AUTOSAR XML (schema 00051)
standard types defined: boolean, uint16, uint32, uint8, Boolean, UInt16, UInt32, UInt8
package /FV/Comm
  pdu DecelIPdu: length=8  # Authentic/plain I-PDU DecelIPdu
    signal DecelISig: start 0, 64 bit, little-endian, system signal DecelSSig
  pdu EngineIPdu: length=8  # Authentic/plain I-PDU EngineIPdu
    signal EngineISig: start 0, 64 bit, little-endian, system signal EngineSSig
  pdu NavIPdu: length=8  # Authentic/plain I-PDU NavIPdu
    signal NavISig: start 0, 64 bit, little-endian, system signal NavSSig
  pdu TcuGwIPdu: length=8  # Authentic/plain I-PDU TcuGwIPdu
    signal TcuGwISig: start 0, 64 bit, little-endian, system signal TcuGwSSig
  pdu V2xIPdu: length=8  # Authentic/plain I-PDU V2xIPdu
    signal V2xISig: start 0, 64 bit, little-endian, system signal V2xSSig
package /FV/If
  23 x sender receiver interface:
    AmbientCmd  # Sender/receiver interface AmbientCmd
      data color: type=Byte8Array
    BodyCmd  # Sender/receiver interface BodyCmd
      data cmd: type=Byte8Array
    BrakeForce  # Sender/receiver interface BrakeForce
      data force: type=Byte8Array
    ComfortMode  # Sender/receiver interface ComfortMode
      data mode: type=Byte8Array
    DecelReq  # Sender/receiver interface DecelReq
      data decel: type=Byte8Array
    DiagCmd  # Sender/receiver interface DiagCmd
      data cmd: type=Byte8Array
    DoorCmd  # Sender/receiver interface DoorCmd
      data lock: type=Byte8Array
    EmisData  # Sender/receiver interface EmisData
      data emis: type=Byte8Array
    EngineCmd  # Sender/receiver interface EngineCmd
      data torque: type=Byte8Array
    FwPolicy  # Sender/receiver interface FwPolicy
      data rule: type=Byte8Array
    HvacCmd  # Sender/receiver interface HvacCmd
      data temp: type=Byte8Array
    LaneData  # Sender/receiver interface LaneData
      data lanes: type=Byte8Array
    LightCmd  # Sender/receiver interface LightCmd
      data level: type=Byte8Array
    MediaReq  # Sender/receiver interface MediaReq
      data payload: type=Byte8Array
    MediaStream  # Sender/receiver interface MediaStream
      data stream: type=Byte8Array
    NavRoute  # Sender/receiver interface NavRoute
      data route: type=Byte8Array
    ObjData  # Sender/receiver interface ObjData
      data objects: type=Byte8Array
    OtaCmd  # Sender/receiver interface OtaCmd
      data pkg: type=Byte8Array
    RemoteSvc  # Sender/receiver interface RemoteSvc
      data val: type=Byte8Array
    SteerAngle  # Sender/receiver interface SteerAngle
      data angle: type=Byte8Array
    TailCmd  # Sender/receiver interface TailCmd
      data level: type=Byte8Array
    TransGear  # Sender/receiver interface TransGear
      data gear: type=Byte8Array
    V2xMsg  # Sender/receiver interface V2xMsg
      data msg: type=Byte8Array
package /FV/Network
  can cluster Backbone: baudrate=500000, can-fd-baudrate=2000000
    can physical channel Ch0
      comm-connectors:
        AdasEcu/CanConn0
        BodyEcu/CanConn0
        ChassisEcu/CanConn0
        GatewayEcu/CanConn0
        IviEcu/CanConn0
        LightEcu/CanConn0
        PtEcu/CanConn0
        TelematicsEcu/CanConn0
      frame Frame_BodyIPdu: id 0x100, from GatewayEcu, to BodyEcu, frame-length=8, can-addressing-mode=STANDARD, can-frame-rx-behavior=CAN-FD, can-frame-tx-behavior=CAN-FD
        pdu BodyIPdu: length=8  # Authentic/plain I-PDU BodyIPdu
          signal BodyISig: start 0, 64 bit, little-endian, system signal BodySSig
      frame Frame_ComfortIPdu: id 0x101, from GatewayEcu, frame-length=8, can-addressing-mode=STANDARD, can-frame-rx-behavior=CAN-FD, can-frame-tx-behavior=CAN-FD
        pdu ComfortIPdu: length=8  # Authentic/plain I-PDU ComfortIPdu
          signal ComfortISig: start 0, 64 bit, little-endian, system signal ComfortSSig
      frame Frame_DecelSecuredIPdu: id 0x102, frame-length=16, can-addressing-mode=STANDARD, can-frame-rx-behavior=CAN-FD, can-frame-tx-behavior=CAN-FD
        secured i pdu DecelSecuredIPdu: length=13, payload=Trg_DecelIPdu, secure-communication-props={auth-algorithm=CMAC, auth-info-tx-length=32, data-id=259, freshness-value-id=4, freshness-value-length=8, freshness-value-tx-length=8}, use-as-cryptographic-i-pdu=false  # SecOC secured I-PDU DecelSecuredIPdu
      frame Frame_EngineSecuredIPdu: id 0x103, frame-length=16, can-addressing-mode=STANDARD, can-frame-rx-behavior=CAN-FD, can-frame-tx-behavior=CAN-FD
        secured i pdu EngineSecuredIPdu: length=13, payload=Trg_EngineIPdu, secure-communication-props={auth-algorithm=CMAC, auth-info-tx-length=32, data-id=260, freshness-value-id=5, freshness-value-length=8, freshness-value-tx-length=8}, use-as-cryptographic-i-pdu=false  # SecOC secured I-PDU EngineSecuredIPdu
      frame Frame_LightIPdu: id 0x104, from GatewayEcu, to LightEcu, frame-length=8, can-addressing-mode=STANDARD, can-frame-rx-behavior=CAN-FD, can-frame-tx-behavior=CAN-FD
        pdu LightIPdu: length=8  # Authentic/plain I-PDU LightIPdu
          signal LightISig: start 0, 64 bit, little-endian, system signal LightSSig
      frame Frame_NavSecuredIPdu: id 0x105, frame-length=16, can-addressing-mode=STANDARD, can-frame-rx-behavior=CAN-FD, can-frame-tx-behavior=CAN-FD
        secured i pdu NavSecuredIPdu: length=13, payload=Trg_NavIPdu, secure-communication-props={auth-algorithm=CMAC, auth-info-tx-length=32, data-id=256, freshness-value-id=1, freshness-value-length=8, freshness-value-tx-length=8}, use-as-cryptographic-i-pdu=false  # SecOC secured I-PDU NavSecuredIPdu
      frame Frame_OtaIPdu: id 0x106, from TelematicsEcu, to GatewayEcu, frame-length=8, can-addressing-mode=STANDARD, can-frame-rx-behavior=CAN-FD, can-frame-tx-behavior=CAN-FD
        pdu OtaIPdu: length=8  # Authentic/plain I-PDU OtaIPdu
          signal OtaISig: start 0, 64 bit, little-endian, system signal OtaSSig
      frame Frame_TcuGwSecuredIPdu: id 0x107, frame-length=16, can-addressing-mode=STANDARD, can-frame-rx-behavior=CAN-FD, can-frame-tx-behavior=CAN-FD
        secured i pdu TcuGwSecuredIPdu: length=13, payload=Trg_TcuGwIPdu, secure-communication-props={auth-algorithm=CMAC, auth-info-tx-length=32, data-id=257, freshness-value-id=2, freshness-value-length=8, freshness-value-tx-length=8}, use-as-cryptographic-i-pdu=false  # SecOC secured I-PDU TcuGwSecuredIPdu
      frame Frame_V2xSecuredIPdu: id 0x108, frame-length=16, can-addressing-mode=STANDARD, can-frame-rx-behavior=CAN-FD, can-frame-tx-behavior=CAN-FD
        secured i pdu V2xSecuredIPdu: length=13, payload=Trg_V2xIPdu, secure-communication-props={auth-algorithm=CMAC, auth-info-tx-length=32, data-id=258, freshness-value-id=3, freshness-value-length=8, freshness-value-tx-length=8}, use-as-cryptographic-i-pdu=false  # SecOC secured I-PDU V2xSecuredIPdu
      pdu triggering Trg_DecelIPdu: pdu=DecelIPdu, from AdasEcu, to ChassisEcu
      pdu triggering Trg_EngineIPdu: pdu=EngineIPdu, from GatewayEcu, to PtEcu
      pdu triggering Trg_NavIPdu: pdu=NavIPdu, from IviEcu, to GatewayEcu
      pdu triggering Trg_TcuGwIPdu: pdu=TcuGwIPdu, from TelematicsEcu, to GatewayEcu
      pdu triggering Trg_V2xIPdu: pdu=V2xIPdu, from TelematicsEcu, to GatewayEcu
package /FV/Swc
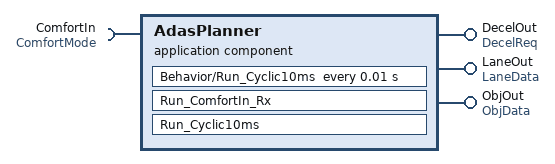
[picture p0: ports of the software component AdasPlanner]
  application sw component type AdasPlanner  # Application software component type AdasPlanner
    require port ComfortIn: required-interface=ComfortMode
    provide port DecelOut: provided-interface=DecelReq
    provide port LaneOut: provided-interface=LaneData
    provide port ObjOut: provided-interface=ObjData
    behavior Behavior
      data received event Dre_ComfortIn: start-on-event=Run_ComfortIn_Rx, data=ComfortIn.mode
      timing event Tev_Cyclic10ms: start-on-event=Behavior/Run_Cyclic10ms, period=0.01
      runnable Run_ComfortIn_Rx
        data-receive-point-by-arguments:
          access Rcv_ComfortIn: accessed-variable=ComfortIn.mode
      runnable Run_Cyclic10ms
        data-send-points:
          access Snd_DecelOut: accessed-variable=DecelOut.decel
          access Snd_LaneOut: accessed-variable=LaneOut.lanes
          access Snd_ObjOut: accessed-variable=ObjOut.objects
  swc implementation AdasPlanner_Impl: programming-language=C, sw-version=1.0.0, behavior=AdasPlanner/Behavior
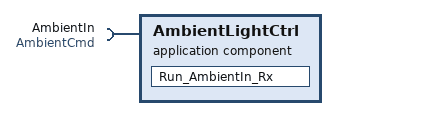
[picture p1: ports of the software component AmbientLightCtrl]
  application sw component type AmbientLightCtrl  # Application software component type AmbientLightCtrl
    require port AmbientIn: required-interface=AmbientCmd
    behavior Behavior
      data received event Dre_AmbientIn: start-on-event=Run_AmbientIn_Rx, data=AmbientIn.color
      runnable Run_AmbientIn_Rx
        data-receive-point-by-arguments:
          access Rcv_AmbientIn: accessed-variable=AmbientIn.color
  swc implementation AmbientLightCtrl_Impl: programming-language=C, sw-version=1.0.0, behavior=AmbientLightCtrl/Behavior
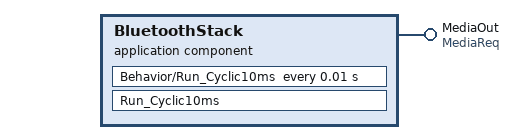
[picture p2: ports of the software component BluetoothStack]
  application sw component type BluetoothStack  # Application software component type BluetoothStack
    provide port MediaOut: provided-interface=MediaReq
    behavior Behavior
      timing event Tev_Cyclic10ms: start-on-event=Behavior/Run_Cyclic10ms, period=0.01
      runnable Run_Cyclic10ms
        data-send-points:
          access Snd_MediaOut: accessed-variable=MediaOut.payload
  swc implementation BluetoothStack_Impl: programming-language=C, sw-version=1.0.0, behavior=BluetoothStack/Behavior
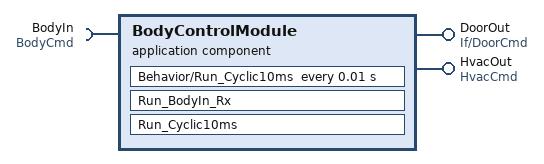
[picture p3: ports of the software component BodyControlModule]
  application sw component type BodyControlModule  # Application software component type BodyControlModule
    require port BodyIn: required-interface=BodyCmd
    provide port DoorOut: provided-interface=If/DoorCmd
    provide port HvacOut: provided-interface=HvacCmd
    behavior Behavior
      data received event Dre_BodyIn: start-on-event=Run_BodyIn_Rx, data=BodyIn.cmd
      timing event Tev_Cyclic10ms: start-on-event=Behavior/Run_Cyclic10ms, period=0.01
      runnable Run_BodyIn_Rx
        data-receive-point-by-arguments:
          access Rcv_BodyIn: accessed-variable=BodyIn.cmd
      runnable Run_Cyclic10ms
        data-send-points:
          access Snd_DoorOut: accessed-variable=DoorOut.lock
          access Snd_HvacOut: accessed-variable=HvacOut.temp
  swc implementation BodyControlModule_Impl: programming-language=C, sw-version=1.0.0, behavior=BodyControlModule/Behavior
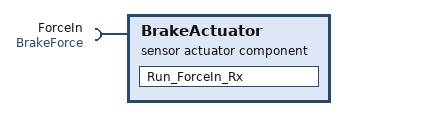
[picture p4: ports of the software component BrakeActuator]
  sensor actuator sw component type BrakeActuator  # Sensor/actuator software component type BrakeActuator
    require port ForceIn: required-interface=BrakeForce
    behavior Behavior
      data received event Dre_ForceIn: start-on-event=Run_ForceIn_Rx, data=ForceIn.force
      runnable Run_ForceIn_Rx
        data-receive-point-by-arguments:
          access Rcv_ForceIn: accessed-variable=ForceIn.force
  swc implementation BrakeActuator_Impl: programming-language=C, sw-version=1.0.0, behavior=BrakeActuator/Behavior
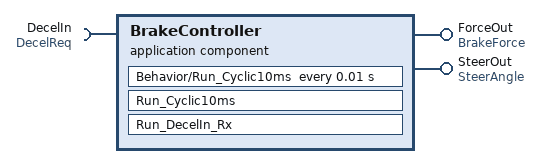
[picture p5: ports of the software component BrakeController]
  application sw component type BrakeController  # Application software component type BrakeController
    require port DecelIn: required-interface=DecelReq
    provide port ForceOut: provided-interface=BrakeForce
    provide port SteerOut: provided-interface=SteerAngle
    behavior Behavior
      data received event Dre_DecelIn: start-on-event=Run_DecelIn_Rx, data=DecelIn.decel
      timing event Tev_Cyclic10ms: start-on-event=Behavior/Run_Cyclic10ms, period=0.01
      runnable Run_Cyclic10ms
        data-send-points:
          access Snd_ForceOut: accessed-variable=ForceOut.force
          access Snd_SteerOut: accessed-variable=SteerOut.angle
      runnable Run_DecelIn_Rx
        data-receive-point-by-arguments:
          access Rcv_DecelIn: accessed-variable=DecelIn.decel
  swc implementation BrakeController_Impl: programming-language=C, sw-version=1.0.0, behavior=BrakeController/Behavior
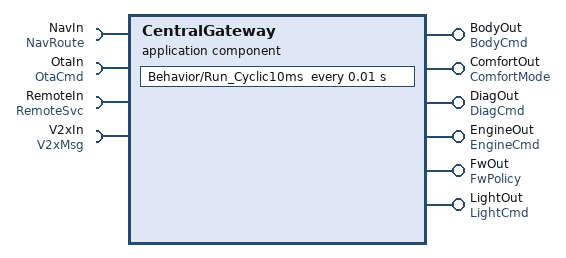
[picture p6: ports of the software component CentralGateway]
  application sw component type CentralGateway  # Application software component type CentralGateway
    6 x provide port:
      BodyOut: provided-interface=BodyCmd
      ComfortOut: provided-interface=ComfortMode
      DiagOut: provided-interface=DiagCmd
      EngineOut: provided-interface=EngineCmd
      FwOut: provided-interface=FwPolicy
      LightOut: provided-interface=LightCmd
    4 x require port:
      NavIn: required-interface=NavRoute
      OtaIn: required-interface=OtaCmd
      RemoteIn: required-interface=RemoteSvc
      V2xIn: required-interface=V2xMsg
    behavior Behavior
      4 x data received event:
        Dre_NavIn: start-on-event=Run_NavIn_Rx, data=NavIn.route
        Dre_OtaIn: start-on-event=Run_OtaIn_Rx, data=OtaIn.pkg
        Dre_RemoteIn: start-on-event=Run_RemoteIn_Rx, data=RemoteIn.val
        Dre_V2xIn: start-on-event=Run_V2xIn_Rx, data=V2xIn.msg
      timing event Tev_Cyclic10ms: start-on-event=Behavior/Run_Cyclic10ms, period=0.01
      5 x runnable:
        Run_Cyclic10ms
          data-send-points:
            6 x access:
              Snd_BodyOut: accessed-variable=BodyOut.cmd
              Snd_ComfortOut: accessed-variable=ComfortOut.mode
              Snd_DiagOut: accessed-variable=DiagOut.cmd
              Snd_EngineOut: accessed-variable=EngineOut.torque
              Snd_FwOut: accessed-variable=FwOut.rule
              Snd_LightOut: accessed-variable=LightOut.level
        Run_NavIn_Rx
          data-receive-point-by-arguments:
            access Rcv_NavIn: accessed-variable=NavIn.route
        Run_OtaIn_Rx
          data-receive-point-by-arguments:
            access Rcv_OtaIn: accessed-variable=OtaIn.pkg
        Run_RemoteIn_Rx
          data-receive-point-by-arguments:
            access Rcv_RemoteIn: accessed-variable=RemoteIn.val
        Run_V2xIn_Rx
          data-receive-point-by-arguments:
            access Rcv_V2xIn: accessed-variable=V2xIn.msg
  swc implementation CentralGateway_Impl: programming-language=C, sw-version=1.0.0, behavior=CentralGateway/Behavior
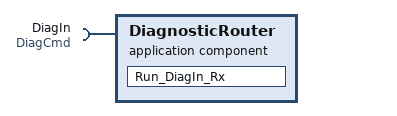
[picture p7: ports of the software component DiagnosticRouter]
  application sw component type DiagnosticRouter  # Application software component type DiagnosticRouter
    require port DiagIn: required-interface=DiagCmd
    behavior Behavior
      data received event Dre_DiagIn: start-on-event=Run_DiagIn_Rx, data=DiagIn.cmd
      runnable Run_DiagIn_Rx
        data-receive-point-by-arguments:
          access Rcv_DiagIn: accessed-variable=DiagIn.cmd
  swc implementation DiagnosticRouter_Impl: programming-language=C, sw-version=1.0.0, behavior=DiagnosticRouter/Behavior
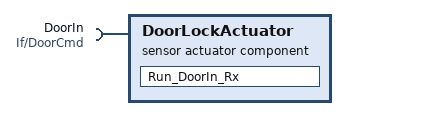
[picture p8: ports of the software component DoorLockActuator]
  sensor actuator sw component type DoorLockActuator  # Sensor/actuator software component type DoorLockActuator
    require port DoorIn: required-interface=If/DoorCmd
    behavior Behavior
      data received event Dre_DoorIn: start-on-event=Run_DoorIn_Rx, data=DoorIn.lock
      runnable Run_DoorIn_Rx
        data-receive-point-by-arguments:
          access Rcv_DoorIn: accessed-variable=DoorIn.lock
  swc implementation DoorLockActuator_Impl: programming-language=C, sw-version=1.0.0, behavior=DoorLockActuator/Behavior
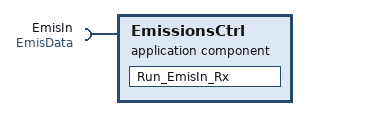
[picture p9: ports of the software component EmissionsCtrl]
  application sw component type EmissionsCtrl  # Application software component type EmissionsCtrl
    require port EmisIn: required-interface=EmisData
    behavior Behavior
      data received event Dre_EmisIn: start-on-event=Run_EmisIn_Rx, data=EmisIn.emis
      runnable Run_EmisIn_Rx
        data-receive-point-by-arguments:
          access Rcv_EmisIn: accessed-variable=EmisIn.emis
  swc implementation EmissionsCtrl_Impl: programming-language=C, sw-version=1.0.0, behavior=EmissionsCtrl/Behavior
  application sw component type EngineController  # Application software component type EngineController
    provide port EmisOut: provided-interface=EmisData
    require port EngIn: required-interface=EngineCmd
    provide port TransOut: provided-interface=TransGear
    behavior Behavior
      data received event Dre_EngIn: start-on-event=Run_EngIn_Rx, data=EngIn.torque
      timing event Tev_Cyclic10ms: start-on-event=Behavior/Run_Cyclic10ms, period=0.01
      runnable Run_Cyclic10ms
        data-send-points:
          access Snd_EmisOut: accessed-variable=EmisOut.emis
          access Snd_TransOut: accessed-variable=TransOut.gear
      runnable Run_EngIn_Rx
        data-receive-point-by-arguments:
          access Rcv_EngIn: accessed-variable=EngIn.torque
  swc implementation EngineController_Impl: programming-language=C, sw-version=1.0.0, behavior=EngineController/Behavior
  application sw component type FirewallManager  # Application software component type FirewallManager
    require port FwIn: required-interface=FwPolicy
    behavior Behavior
      data received event Dre_FwIn: start-on-event=Run_FwIn_Rx, data=FwIn.rule
      runnable Run_FwIn_Rx
        data-receive-point-by-arguments:
          access Rcv_FwIn: accessed-variable=FwIn.rule
  swc implementation FirewallManager_Impl: programming-language=C, sw-version=1.0.0, behavior=FirewallManager/Behavior
  composition sw component type FullVehicle  # Composition FullVehicle
    24 x component:
      adas: type=AdasPlanner
      ambientLight: type=AmbientLightCtrl
      bcm: type=BodyControlModule
      brakeAct: type=BrakeActuator
      brakeCtl: type=BrakeController
      btStack: type=BluetoothStack
      cgw: type=CentralGateway
      diagRouter: type=DiagnosticRouter
      doorLock: type=DoorLockActuator
      emisCtl: type=EmissionsCtrl
      engineCtl: type=EngineController
      firewallMgr: type=FirewallManager
      headlight: type=HeadlightCtrl
      hvacCtl: type=HvacController
      ivi: type=InfotainmentHU
      laneKeep: type=LaneKeepAssist
      mediaPlayer: type=MediaPlayer
      objDetect: type=ObjectDetector
      otaManager: type=OtaManager
      steerCtl: type=SteeringController
      taillight: type=TaillightCtrl
      tcu: type=Swc/TelematicsUnit
      transCtl: type=TransmissionCtrl
      v2xStack: type=V2xStack
    connect adas.DecelOut -> brakeCtl.DecelIn
    connect adas.LaneOut -> laneKeep.LaneIn
    connect adas.ObjOut -> objDetect.ObjIn
    connect bcm.DoorOut -> doorLock.DoorIn
    connect bcm.HvacOut -> hvacCtl.HvacIn
    connect brakeCtl.ForceOut -> brakeAct.ForceIn
    connect brakeCtl.SteerOut -> steerCtl.SteerIn
    connect btStack.MediaOut -> ivi.MediaIn
    connect engineCtl.EmisOut -> emisCtl.EmisIn
    connect engineCtl.TransOut -> transCtl.TransIn
    connect cgw.BodyOut -> bcm.BodyIn
    connect cgw.DiagOut -> diagRouter.DiagIn
    connect cgw.EngineOut -> engineCtl.EngIn
    connect cgw.FwOut -> firewallMgr.FwIn
    connect cgw.LightOut -> headlight.LightIn
    connect headlight.AmbientOut -> ambientLight.AmbientIn
    connect headlight.TailOut -> taillight.TailIn
    connect ivi.NavOut -> cgw.NavIn
    connect ivi.StreamOut -> mediaPlayer.StreamIn
    connect otaManager.OtaOut -> cgw.OtaIn
    connect tcu.RemoteOut -> cgw.RemoteIn
    connect v2xStack.V2xOut -> cgw.V2xIn
  application sw component type HeadlightCtrl  # Application software component type HeadlightCtrl
    provide port AmbientOut: provided-interface=AmbientCmd
    require port LightIn: required-interface=LightCmd
    provide port TailOut: provided-interface=TailCmd
    behavior Behavior
      data received event Dre_LightIn: start-on-event=Run_LightIn_Rx, data=LightIn.level
      timing event Tev_Cyclic10ms: start-on-event=Behavior/Run_Cyclic10ms, period=0.01
      runnable Run_Cyclic10ms
        data-send-points:
          access Snd_AmbientOut: accessed-variable=AmbientOut.color
          access Snd_TailOut: accessed-variable=TailOut.level
      runnable Run_LightIn_Rx
        data-receive-point-by-arguments:
          access Rcv_LightIn: accessed-variable=LightIn.level
  swc implementation HeadlightCtrl_Impl: programming-language=C, sw-version=1.0.0, behavior=HeadlightCtrl/Behavior
  application sw component type HvacController  # Application software component type HvacController
    require port HvacIn: required-interface=HvacCmd
    behavior Behavior
      data received event Dre_HvacIn: start-on-event=Run_HvacIn_Rx, data=HvacIn.temp
      runnable Run_HvacIn_Rx
        data-receive-point-by-arguments:
          access Rcv_HvacIn: accessed-variable=HvacIn.temp
  swc implementation HvacController_Impl: programming-language=C, sw-version=1.0.0, behavior=HvacController/Behavior
  application sw component type InfotainmentHU  # Application software component type InfotainmentHU
    require port MediaIn: required-interface=MediaReq
    provide port NavOut: provided-interface=NavRoute
    provide port StreamOut: provided-interface=MediaStream
    behavior Behavior
      data received event Dre_MediaIn: start-on-event=Run_MediaIn_Rx, data=MediaIn.payload
      timing event Tev_Cyclic10ms: start-on-event=Behavior/Run_Cyclic10ms, period=0.01
      runnable Run_Cyclic10ms
        data-send-points:
          access Snd_NavOut: accessed-variable=NavOut.route
          access Snd_StreamOut: accessed-variable=StreamOut.stream
      runnable Run_MediaIn_Rx
        data-receive-point-by-arguments:
          access Rcv_MediaIn: accessed-variable=MediaIn.payload
  swc implementation InfotainmentHU_Impl: programming-language=C, sw-version=1.0.0, behavior=InfotainmentHU/Behavior
  application sw component type LaneKeepAssist  # Application software component type LaneKeepAssist
    require port LaneIn: required-interface=LaneData
    behavior Behavior
      data received event Dre_LaneIn: start-on-event=Run_LaneIn_Rx, data=LaneIn.lanes
      runnable Run_LaneIn_Rx
        data-receive-point-by-arguments:
          access Rcv_LaneIn: accessed-variable=LaneIn.lanes
  swc implementation LaneKeepAssist_Impl: programming-language=C, sw-version=1.0.0, behavior=LaneKeepAssist/Behavior
  application sw component type MediaPlayer  # Application software component type MediaPlayer
    require port StreamIn: required-interface=MediaStream
    behavior Behavior
      data received event Dre_StreamIn: start-on-event=Run_StreamIn_Rx, data=StreamIn.stream
      runnable Run_StreamIn_Rx
        data-receive-point-by-arguments:
          access Rcv_StreamIn: accessed-variable=StreamIn.stream
  swc implementation MediaPlayer_Impl: programming-language=C, sw-version=1.0.0, behavior=MediaPlayer/Behavior
  application sw component type ObjectDetector  # Application software component type ObjectDetector
    require port ObjIn: required-interface=ObjData
    behavior Behavior
      data received event Dre_ObjIn: start-on-event=Run_ObjIn_Rx, data=ObjIn.objects
      runnable Run_ObjIn_Rx
        data-receive-point-by-arguments:
          access Rcv_ObjIn: accessed-variable=ObjIn.objects
  swc implementation ObjectDetector_Impl: programming-language=C, sw-version=1.0.0, behavior=ObjectDetector/Behavior
  application sw component type OtaManager  # Application software component type OtaManager
    provide port OtaOut: provided-interface=OtaCmd
    behavior Behavior
      timing event Tev_Cyclic10ms: start-on-event=Behavior/Run_Cyclic10ms, period=0.01
      runnable Run_Cyclic10ms
        data-send-points:
          access Snd_OtaOut: accessed-variable=OtaOut.pkg
  swc implementation OtaManager_Impl: programming-language=C, sw-version=1.0.0, behavior=OtaManager/Behavior
  sensor actuator sw component type SteeringController  # Sensor/actuator software component type SteeringController
    require port SteerIn: required-interface=SteerAngle
    behavior Behavior
      data received event Dre_SteerIn: start-on-event=Run_SteerIn_Rx, data=SteerIn.angle
      runnable Run_SteerIn_Rx
        data-receive-point-by-arguments:
          access Rcv_SteerIn: accessed-variable=SteerIn.angle
  swc implementation SteeringController_Impl: programming-language=C, sw-version=1.0.0, behavior=SteeringController/Behavior
  sensor actuator sw component type TaillightCtrl  # Sensor/actuator software component type TaillightCtrl
    require port TailIn: required-interface=TailCmd
    behavior Behavior
      data received event Dre_TailIn: start-on-event=Run_TailIn_Rx, data=TailIn.level
      runnable Run_TailIn_Rx
        data-receive-point-by-arguments:
          access Rcv_TailIn: accessed-variable=TailIn.level
  swc implementation TaillightCtrl_Impl: programming-language=C, sw-version=1.0.0, behavior=TaillightCtrl/Behavior
  application sw component type TelematicsUnit  # Application software component type TelematicsUnit
    provide port RemoteOut: provided-interface=RemoteSvc
    behavior Behavior
      timing event Tev_Cyclic10ms: start-on-event=Behavior/Run_Cyclic10ms, period=0.01
      runnable Run_Cyclic10ms
        data-send-points:
          access Snd_RemoteOut: accessed-variable=RemoteOut.val
  swc implementation TelematicsUnit_Impl: programming-language=C, sw-version=1.0.0, behavior=TelematicsUnit/Behavior
  application sw component type TransmissionCtrl  # Application software component type TransmissionCtrl
    require port TransIn: required-interface=TransGear
    behavior Behavior
      data received event Dre_TransIn: start-on-event=Run_TransIn_Rx, data=TransIn.gear
      runnable Run_TransIn_Rx
        data-receive-point-by-arguments:
          access Rcv_TransIn: accessed-variable=TransIn.gear
  swc implementation TransmissionCtrl_Impl: programming-language=C, sw-version=1.0.0, behavior=TransmissionCtrl/Behavior
  application sw component type V2xStack  # Application software component type V2xStack
    provide port V2xOut: provided-interface=V2xMsg
    behavior Behavior
      timing event Tev_Cyclic10ms: start-on-event=Behavior/Run_Cyclic10ms, period=0.01
      runnable Run_Cyclic10ms
        data-send-points:
          access Snd_V2xOut: accessed-variable=V2xOut.msg
  swc implementation V2xStack_Impl: programming-language=C, sw-version=1.0.0, behavior=V2xStack/Behavior
package /FV/Topology
  ecu instance AdasEcu: sleep-mode-supported=false, wake-up-over-bus-supported=false  # ECU instance AdasEcu
    can communication controller CanCtrl0: wake-up-by-controller-supported=false
    can communication connector CanConn0: comm-controller=AdasEcu/CanCtrl0
  ecu instance BodyEcu: sleep-mode-supported=false, wake-up-over-bus-supported=false  # ECU instance BodyEcu
    can communication controller CanCtrl0: wake-up-by-controller-supported=false
    can communication connector CanConn0: comm-controller=BodyEcu/CanCtrl0
  ecu instance ChassisEcu: sleep-mode-supported=false, wake-up-over-bus-supported=false  # ECU instance ChassisEcu
    can communication controller CanCtrl0: wake-up-by-controller-supported=false
    can communication connector CanConn0: comm-controller=ChassisEcu/CanCtrl0
  system FullVeh: category=SYSTEM_EXTRACT  # System extract FullVeh
    system mapping Map
      data-mappings:
        data-element=Root.DecelOut.decel, system-signal=DecelSSig
        data-element=Root.BodyOut.cmd, system-signal=BodySSig
        data-element=Root.ComfortOut.mode, system-signal=ComfortSSig
        data-element=Root.EngineOut.torque, system-signal=EngineSSig
        data-element=Root.LightOut.level, system-signal=LightSSig
        data-element=Root.NavOut.route, system-signal=NavSSig
        data-element=Root.OtaOut.pkg, system-signal=OtaSSig
        data-element=Root.RemoteOut.val, system-signal=TcuGwSSig
        data-element=Root.V2xOut.msg, system-signal=V2xSSig
      sw-mappings:
        8 x swc to ecu mapping:
          ToAdas: component=[adas, laneKeep, objDetect], ecu-instance=AdasEcu
          ToBody: component=[bcm, doorLock, hvacCtl], ecu-instance=Topology/BodyEcu
          ToChassis: component=[brakeAct, brakeCtl, steerCtl], ecu-instance=ChassisEcu
          ToGateway: component=[cgw, diagRouter, firewallMgr], ecu-instance=Topology/GatewayEcu
          ToIvi: component=[btStack, ivi, mediaPlayer], ecu-instance=IviEcu
          ToLight: component=[ambientLight, headlight, taillight], ecu-instance=LightEcu
          ToPt: component=[emisCtl, engineCtl, transCtl], ecu-instance=PtEcu
          ToTelematics: component=[otaManager, tcu, v2xStack], ecu-instance=Topology/TelematicsEcu
    root-software-compositions:
      root sw composition prototype Root: software-composition=FullVehicle
  5 x ecu instance, all with sleep-mode-supported=false, wake-up-over-bus-supported=false:
    GatewayEcu  # ECU instance GatewayEcu
      can communication controller CanCtrl0: wake-up-by-controller-supported=false
      can communication connector CanConn0: comm-controller=GatewayEcu/CanCtrl0
    IviEcu  # ECU instance IviEcu
      can communication controller CanCtrl0: wake-up-by-controller-supported=false
      can communication connector CanConn0: comm-controller=IviEcu/CanCtrl0
    LightEcu  # ECU instance LightEcu
      can communication controller CanCtrl0: wake-up-by-controller-supported=false
      can communication connector CanConn0: comm-controller=LightEcu/CanCtrl0
    PtEcu  # ECU instance PtEcu
      can communication controller CanCtrl0: wake-up-by-controller-supported=false
      can communication connector CanConn0: comm-controller=PtEcu/CanCtrl0
    TelematicsEcu  # ECU instance TelematicsEcu
      can communication controller CanCtrl0: wake-up-by-controller-supported=false
      can communication connector CanConn0: comm-controller=TelematicsEcu/CanCtrl0
package /Platform/ImplementationDataTypes
  impl type Byte8Array: category=ARRAY
    element Element: array-size=8, array-size-semantics=FIXED-SIZE, implementation-data-type=UInt8
package /S10API/Comm
  pdu gwToBodyIPdu: length=8  # Authentic/plain I-PDU gwToBodyIPdu
    signal gwToBodyISig: start 0, 64 bit, little-endian, system signal gwToBodySSig
  pdu portalToTcuIPdu: length=8  # Authentic/plain I-PDU portalToTcuIPdu
    signal portalToTcuISig: start 0, 64 bit, little-endian, system signal portalToTcuSSig
  pdu tcuToGwIPdu: length=8  # Authentic/plain I-PDU tcuToGwIPdu
    signal tcuToGwISig: start 0, 64 bit, little-endian, system signal tcuToGwSSig
package /S10API/If
  sender receiver interface DoorCmd  # Sender/receiver interface DoorCmd
    data val: type=Byte8Array
  sender receiver interface TelemCmd  # Sender/receiver interface TelemCmd
    data val: type=Byte8Array
  sender receiver interface WebAuthSvc  # Sender/receiver interface WebAuthSvc
    data val: type=Byte8Array
package /S10API/Network
  can cluster Backbone: baudrate=500000, can-fd-baudrate=2000000
    can physical channel Ch0: comm-connectors=[BodyEcu/CanConn0, GatewayEcu/CanConn0, TelematicsEcu/CanConn0]
      frame Frame_gwToBodySecuredIPdu: id 0x400, frame-length=16, can-addressing-mode=STANDARD, can-frame-rx-behavior=CAN-FD, can-frame-tx-behavior=CAN-FD
        secured i pdu gwToBodySecuredIPdu: length=13, payload=Trg_gwToBodyIPdu, secure-communication-props={auth-algorithm=CMAC, auth-info-tx-length=32, data-id=263, freshness-value-id=1, freshness-value-length=8, freshness-value-tx-length=8}, use-as-cryptographic-i-pdu=false  # SecOC secured I-PDU gwToBodySecuredIPdu
      frame Frame_portalToTcuSecuredIPdu: id 0x401, frame-length=16, can-addressing-mode=STANDARD, can-frame-rx-behavior=CAN-FD, can-frame-tx-behavior=CAN-FD
        secured i pdu portalToTcuSecuredIPdu: length=13, payload=Trg_portalToTcuIPdu, secure-communication-props={auth-algorithm=CMAC, auth-info-tx-length=32, data-id=261, freshness-value-id=1, freshness-value-length=8, freshness-value-tx-length=8}, use-as-cryptographic-i-pdu=false  # SecOC secured I-PDU portalToTcuSecuredIPdu
      frame Frame_tcuToGwSecuredIPdu: id 0x402, frame-length=16, can-addressing-mode=STANDARD, can-frame-rx-behavior=CAN-FD, can-frame-tx-behavior=CAN-FD
        secured i pdu tcuToGwSecuredIPdu: length=13, payload=Trg_tcuToGwIPdu, secure-communication-props={auth-algorithm=CMAC, auth-info-tx-length=32, data-id=262, freshness-value-id=1, freshness-value-length=8, freshness-value-tx-length=8}, use-as-cryptographic-i-pdu=false  # SecOC secured I-PDU tcuToGwSecuredIPdu
      pdu triggering Trg_gwToBodyIPdu: pdu=gwToBodyIPdu, from GatewayEcu, to BodyEcu
      pdu triggering Trg_portalToTcuIPdu: pdu=portalToTcuIPdu, from TelematicsEcu, to TelematicsEcu
      pdu triggering Trg_tcuToGwIPdu: pdu=tcuToGwIPdu, from TelematicsEcu, to GatewayEcu
package /S10API/Swc
  application sw component type BodyDoorControl  # Application software component type BodyDoorControl
    require port gwToBodyIn: required-interface=If/DoorCmd
    behavior Behavior
      data received event Dre_gwToBodyIn: start-on-event=Run_gwToBodyIn_Rx, data=gwToBodyIn.val
      runnable Run_gwToBodyIn_Rx
        data-receive-point-by-arguments:
          access Rcv_gwToBodyIn: accessed-variable=gwToBodyIn.val
  swc implementation BodyDoorControl_Impl: programming-language=C, sw-version=1.0.0, behavior=BodyDoorControl/Behavior
  application sw component type DealerPortalApi  # Application software component type DealerPortalApi
    provide port portalToTcuOut: provided-interface=WebAuthSvc
    behavior Behavior
      timing event Tev_Cyclic10ms: start-on-event=Behavior/Run_Cyclic10ms, period=0.01
      runnable Run_Cyclic10ms
        data-send-points:
          access Snd_portalToTcuOut: accessed-variable=portalToTcuOut.val
  swc implementation DealerPortalApi_Impl: programming-language=C, sw-version=1.0.0, behavior=DealerPortalApi/Behavior
  application sw component type GatewayCtrl  # Application software component type GatewayCtrl
    provide port gwToBodyOut: provided-interface=If/DoorCmd
    require port tcuToGwIn: required-interface=TelemCmd
    behavior Behavior
      data received event Dre_tcuToGwIn: start-on-event=Run_tcuToGwIn_Rx, data=tcuToGwIn.val
      timing event Tev_Cyclic10ms: start-on-event=Behavior/Run_Cyclic10ms, period=0.01
      runnable Run_Cyclic10ms
        data-send-points:
          access Snd_gwToBodyOut: accessed-variable=gwToBodyOut.val
      runnable Run_tcuToGwIn_Rx
        data-receive-point-by-arguments:
          access Rcv_tcuToGwIn: accessed-variable=tcuToGwIn.val
  swc implementation GatewayCtrl_Impl: programming-language=C, sw-version=1.0.0, behavior=GatewayCtrl/Behavior
  composition sw component type Root  # Composition Root
    4 x component:
      body: type=BodyDoorControl
      gw: type=GatewayCtrl
      portal: type=DealerPortalApi
      tcu: type=Swc/TelematicsUnit
    connect gw.gwToBodyOut -> body.gwToBodyIn
    connect portal.portalToTcuOut -> tcu.portalToTcuIn
    connect tcu.tcuToGwOut -> gw.tcuToGwIn
  application sw component type TelematicsUnit  # Application software component type TelematicsUnit
    require port portalToTcuIn: required-interface=WebAuthSvc
    provide port tcuToGwOut: provided-interface=TelemCmd
    behavior Behavior
      data received event Dre_portalToTcuIn: start-on-event=Run_portalToTcuIn_Rx, data=portalToTcuIn.val
      timing event Tev_Cyclic10ms: start-on-event=Behavior/Run_Cyclic10ms, period=0.01
      runnable Run_Cyclic10ms
        data-send-points:
          access Snd_tcuToGwOut: accessed-variable=tcuToGwOut.val
      runnable Run_portalToTcuIn_Rx
        data-receive-point-by-arguments:
          access Rcv_portalToTcuIn: accessed-variable=portalToTcuIn.val
  swc implementation TelematicsUnit_Impl: programming-language=C, sw-version=1.0.0, behavior=TelematicsUnit/Behavior
package /S10API/Topology
  ecu instance BodyEcu: sleep-mode-supported=false, wake-up-over-bus-supported=false  # ECU instance BodyEcu
    can communication controller CanCtrl0: wake-up-by-controller-supported=false
    can communication connector CanConn0: comm-controller=BodyEcu/CanCtrl0
  ecu instance GatewayEcu: sleep-mode-supported=false, wake-up-over-bus-supported=false  # ECU instance GatewayEcu
    can communication controller CanCtrl0: wake-up-by-controller-supported=false
    can communication connector CanConn0: comm-controller=GatewayEcu/CanCtrl0
  ecu instance TelematicsEcu: sleep-mode-supported=false, wake-up-over-bus-supported=false  # ECU instance TelematicsEcu
    can communication controller CanCtrl0: wake-up-by-controller-supported=false
    can communication connector CanConn0: comm-controller=TelematicsEcu/CanCtrl0
  system Veh: category=SYSTEM_EXTRACT  # System extract Veh
    system mapping Map
      data-mappings:
        data-element=Root.portalToTcuOut.val, system-signal=portalToTcuSSig
        data-element=Root.gwToBodyOut.val, system-signal=gwToBodySSig
        data-element=Root.tcuToGwOut.val, system-signal=tcuToGwSSig
      sw-mappings:
        swc to ecu mapping ToBodyEcu: component=body, ecu-instance=Topology/BodyEcu
        swc to ecu mapping ToGatewayEcu: component=gw, ecu-instance=Topology/GatewayEcu
        swc to ecu mapping ToTelematicsEcu: component=[portal, tcu], ecu-instance=Topology/TelematicsEcu
    root-software-compositions:
      root sw composition prototype Root: software-composition=Root
